# LargeDummyDevice register map
File version: 1.0
Registers are 32-bit, read-write, no defined reset value unless marked. A register's access mark holds for its fields unless they carry their own. Offsets are from the block's base; [hi:lo] are bit positions.

## PERIPHERAL_9
Base 0x40008000
0x04 REG_1 — Register 1
  [32:30] FIELD_11, [32:30] FIELD_14, [31:29] FIELD_5, [28] FIELD_4, [31:28] FIELD_13, [32:28] FIELD_18, [30:27] FIELD_17, [28:26] FIELD_15, [21:20] FIELD_7, [22:20] FIELD_20, [10:9] FIELD_10, [8] FIELD_8, [10:7] FIELD_2, [8:6] FIELD_3, [6:4] FIELD_1, [6:2] FIELD_12, [4:1] FIELD_6, [5:1] FIELD_9, [3:1] FIELD_19, [1:0] FIELD_16
0x08 REG_2 — Register 2
  [2] FIELD_1
0x0C REG_3 — Register 3
  [31] FIELD_7, [31:27] FIELD_19, [24:20] FIELD_28, [18] FIELD_15, [18:17] FIELD_25, [15:14] FIELD_21, [17:13] FIELD_5, [13] FIELD_11, [17:13] FIELD_22, [13:12] FIELD_14, [14:11] FIELD_20, [13:10] FIELD_18, [12:9] FIELD_16, [9] FIELD_26, [11:8] FIELD_1, [9:7] FIELD_4, [7] FIELD_24, [9:6] FIELD_8, [9:6] FIELD_9, [9:6] FIELD_12, [5] FIELD_13, [5] FIELD_23, [5:4] FIELD_27, [5:3] FIELD_10, [2] FIELD_2, [6:2] FIELD_17, [1] FIELD_3, [4:1] FIELD_6
0x10 REG_4 — Register 4
  [34:31] FIELD_16, [33:31] FIELD_22, [35:31] FIELD_27, [31:30] FIELD_2, [33:30] FIELD_5, [34:30] FIELD_12, [33:29] FIELD_11, [30:29] FIELD_15, [31:28] FIELD_24, [28:27] FIELD_8, [29:27] FIELD_25, [27:24] FIELD_29, [17] FIELD_6, [18:17] FIELD_21, [18:16] FIELD_32, [19:15] FIELD_23, [15:14] FIELD_4, [16:14] FIELD_13, [13] FIELD_17, [12] FIELD_20, [15:11] FIELD_18, [13:11] FIELD_26, [8] FIELD_30, [8:7] FIELD_9, [11:7] FIELD_19, [7] FIELD_31, [6:5] FIELD_1, [7:4] FIELD_3, [7:3] FIELD_14, [2:1] FIELD_10, [0] FIELD_7, [0] FIELD_28
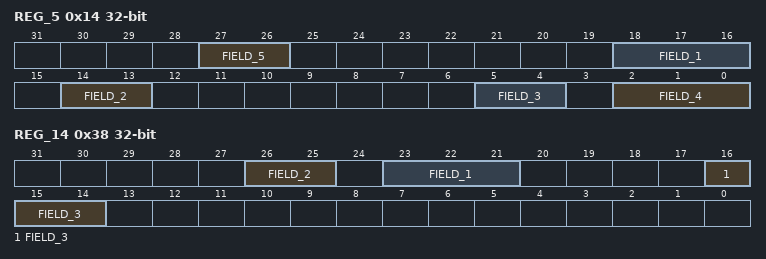
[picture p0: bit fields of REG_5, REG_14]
0x14 REG_5 — Register 5
  [27:26] FIELD_5, [18:16] FIELD_1, [14:13] FIELD_2, [5:4] FIELD_3, [2:0] FIELD_4
0x18 REG_6 — Register 6
  [31:29] FIELD_15, [25:23] FIELD_11, [25:21] FIELD_4, [21] FIELD_5, [25:21] FIELD_18, [24:20] FIELD_13, [20:18] FIELD_10, [18:17] FIELD_7, [16] FIELD_2, [12] FIELD_12, [8:7] FIELD_17, [6] FIELD_3, [6:5] FIELD_16, [4:3] FIELD_9, [5:2] FIELD_14, [5:1] FIELD_1, [1:0] FIELD_6, [1:0] FIELD_8
0x1C REG_7 — Register 7
  [32:31] FIELD_26, [32:29] FIELD_4, [33:29] FIELD_17, [28] FIELD_9, [32:28] FIELD_20, [29:27] FIELD_7, [29:27] FIELD_11, [26] FIELD_12, [29:26] FIELD_21, [27:26] FIELD_29, [29:25] FIELD_1, [26:24] FIELD_2, [25:24] FIELD_13, [20:19] FIELD_15, [19] FIELD_16, [21:19] FIELD_25, [17] FIELD_5, [20:17] FIELD_19, [19:17] FIELD_30, [15] FIELD_23, [14:13] FIELD_6, [12] FIELD_10, [15:12] FIELD_14, [11] FIELD_8, [8:7] FIELD_18, [7:5] FIELD_22, [9:5] FIELD_28, [3:2] FIELD_3, [3:2] FIELD_27, [1] FIELD_24
0x20 REG_8 — Register 8
  [32:31] FIELD_11, [30:26] FIELD_2, [28:26] FIELD_8, [26:24] FIELD_9, [27:23] FIELD_15, [25:22] FIELD_4, [25:21] FIELD_22, [23:21] FIELD_29, [23:20] FIELD_16, [21:20] FIELD_18, [19] FIELD_13, [20:19] FIELD_24, [22:19] FIELD_26, [18] FIELD_1, [20:18] FIELD_19, [15:14] FIELD_12, [13:9] FIELD_21, [8] FIELD_6, [8] FIELD_7, [8:7] FIELD_23, [8:7] FIELD_27, [6] FIELD_14, [5:4] FIELD_17, [7:3] FIELD_5, [7:3] FIELD_10, [4:1] FIELD_3, [2:1] FIELD_25, [1] FIELD_28, [1:0] FIELD_20
0x24 REG_9 — Register 9
  [31:30] FIELD_20, [29:28] FIELD_23, [26:25] FIELD_24, [27:24] FIELD_2, [25:24] FIELD_15, [26:23] FIELD_9, [25:23] FIELD_11, [26:22] FIELD_4, [24:22] FIELD_12, [23:22] FIELD_27, [26:22] FIELD_28, [21] FIELD_6, [23:20] FIELD_17, [22:19] FIELD_13, [22:19] FIELD_21, [18] FIELD_14, [19:17] FIELD_7, [16] FIELD_8, [15] FIELD_16, [10] FIELD_19, [12:9] FIELD_10, [8] FIELD_26, [10:8] FIELD_29, [10:7] FIELD_5, [8:6] FIELD_22, [5:4] FIELD_18, [3] FIELD_1, [7:3] FIELD_3, [3] FIELD_25
0x28 REG_10 — Register 10
  [34:31] FIELD_2, [29:25] FIELD_3, [24:23] FIELD_1, [22:18] FIELD_4, [19:18] FIELD_5, [20:16] FIELD_6, [10:7] FIELD_7
0x2C REG_11 — Register 11
  [33:31] FIELD_30, [30:29] FIELD_6, [31:29] FIELD_20, [26] FIELD_1, [26] FIELD_9, [29:26] FIELD_27, [27:24] FIELD_5, [26:24] FIELD_16, [28:24] FIELD_23, [26:23] FIELD_13, [27:23] FIELD_19, [27:23] FIELD_26, [22] FIELD_25, [24:20] FIELD_18, [23:20] FIELD_28, [23:19] FIELD_4, [19] FIELD_7, [22:18] FIELD_22, [18] FIELD_24, [18] FIELD_29, [21:17] FIELD_8, [17:16] FIELD_2, [17:15] FIELD_15, [16:14] FIELD_12, [14:11] FIELD_11, [12:10] FIELD_17, [9] FIELD_10, [11:7] FIELD_3, [2:1] FIELD_14, [3:0] FIELD_21
0x30 REG_12 — Register 12
  [31] FIELD_1, [30:29] FIELD_2, [23] FIELD_7, [24:20] FIELD_11, [18] FIELD_9, [21:17] FIELD_4, [21:17] FIELD_6, [16:13] FIELD_5, [12:10] FIELD_8, [11:8] FIELD_10, [8:5] FIELD_3, [1] FIELD_12
0x34 REG_13 — Register 13
  [31] FIELD_10, [30:29] FIELD_11, [26:25] FIELD_9, [27:24] FIELD_6, [24:22] FIELD_16, [22:19] FIELD_1, [21:19] FIELD_7, [14] FIELD_3, [18:14] FIELD_15, [16:13] FIELD_13, [12:11] FIELD_5, [11] FIELD_14, [11:10] FIELD_2, [10:6] FIELD_4, [7:5] FIELD_12, [8:4] FIELD_8
0x38 REG_14 — Register 14
  [26:25] FIELD_2, [23:21] FIELD_1, [16:14] FIELD_3
0x3C REG_15 — Register 15
  [33:29] FIELD_4, [30:28] FIELD_2, [31:28] FIELD_21, [27] FIELD_25, [29:26] FIELD_11, [28:24] FIELD_14, [26:23] FIELD_23, [24:20] FIELD_10, [18:17] FIELD_1, [17] FIELD_8, [20:17] FIELD_19, [16:14] FIELD_5, [14] FIELD_6, [15:12] FIELD_9, [15:11] FIELD_3, [12:11] FIELD_16, [10:9] FIELD_13, [12:9] FIELD_22, [10:9] FIELD_24, [9:8] FIELD_17, [11:8] FIELD_18, [10:8] FIELD_20, [5] FIELD_7, [7:3] FIELD_12, [4:1] FIELD_15
0x40 REG_16 — Register 16
  [32:31] FIELD_8, [32:31] FIELD_17, [28] FIELD_6, [26] FIELD_7, [28:26] FIELD_11, [25] FIELD_9, [27:24] FIELD_12, [23:22] FIELD_14, [24:22] FIELD_19, [18] FIELD_20, [21:17] FIELD_23, [16] FIELD_4, [17:13] FIELD_16, [13] FIELD_26, [15:12] FIELD_25, [13:10] FIELD_2, [13:10] FIELD_10, [10:9] FIELD_5, [10:6] FIELD_24, [6:4] FIELD_1, [7:3] FIELD_15, [7:3] FIELD_21, [4:2] FIELD_3, [4:2] FIELD_13, [1] FIELD_18, [2:1] FIELD_22
0x44 REG_17 — Register 17
  [33:31] FIELD_6, [33:31] FIELD_14, [33:31] FIELD_21, [30] FIELD_9, [31:28] FIELD_19, [30:27] FIELD_24, [29:25] FIELD_13, [26:25] FIELD_17, [23:22] FIELD_5, [23:20] FIELD_1, [23:20] FIELD_10, [23:19] FIELD_18, [19:18] FIELD_8, [16:15] FIELD_15, [14] FIELD_11, [11] FIELD_4, [14:10] FIELD_20, [14:10] FIELD_23, [10:9] FIELD_2, [9] FIELD_7, [10:8] FIELD_3, [4] FIELD_16, [7:3] FIELD_12, [0] FIELD_22, [1:0] FIELD_25
0x48 REG_18 — Register 18
  [32:30] FIELD_5, [32:28] FIELD_8, [28:25] FIELD_1, [26:25] FIELD_12, [25:24] FIELD_3, [22:18] FIELD_11, [17:16] FIELD_7, [14] FIELD_14, [17:13] FIELD_2, [12] FIELD_9, [11] FIELD_13, [13:10] FIELD_4, [10:9] FIELD_6, [9:6] FIELD_10
0x4C REG_19 — Register 19
  [31:30] FIELD_7, [25:21] FIELD_6, [22:18] FIELD_10, [20:17] FIELD_2, [19:15] FIELD_4, [13] FIELD_12, [13:10] FIELD_9, [11:9] FIELD_11, [8:6] FIELD_8, [6:5] FIELD_5, [5:4] FIELD_1, [6:4] FIELD_3
0x50 REG_20 — Register 20
  [30:29] FIELD_18, [32:29] FIELD_29, [32:28] FIELD_22, [28:27] FIELD_2, [30:27] FIELD_7, [26] FIELD_3, [30:26] FIELD_10, [25] FIELD_32, [25:24] FIELD_1, [23] FIELD_27, [26:23] FIELD_31, [26:22] FIELD_12, [23:20] FIELD_28, [19] FIELD_8, [21:18] FIELD_20, [19:15] FIELD_13, [17:14] FIELD_25, [16:12] FIELD_6, [11] FIELD_15, [15:11] FIELD_19, [11:10] FIELD_4, [12:10] FIELD_11, [13:10] FIELD_23, [9:8] FIELD_14, [7] FIELD_21, [5] FIELD_16, [5] FIELD_26, [6:4] FIELD_17, [7:4] FIELD_24, [5:4] FIELD_30, [4:2] FIELD_9, [4:1] FIELD_5
0x54 REG_21 — Register 21
  [34:31] FIELD_7, [35:31] FIELD_21, [31:29] FIELD_16, [30:28] FIELD_2, [30:26] FIELD_6, [26] FIELD_20, [27:25] FIELD_3, [26:24] FIELD_12, [26:24] FIELD_15, [24:22] FIELD_14, [23:21] FIELD_24, [20:19] FIELD_26, [18:15] FIELD_9, [14] FIELD_19, [14] FIELD_23, [10] FIELD_18, [10:8] FIELD_1, [8] FIELD_11, [9:5] FIELD_4, [8:5] FIELD_5, [9:5] FIELD_8, [7:3] FIELD_10, [3:2] FIELD_13, [3:2] FIELD_25, [4:1] FIELD_17, [3:1] FIELD_22
0x58 REG_22 — Register 22
  [34:31] FIELD_14, [33:31] FIELD_31, [31:30] FIELD_24, [30:29] FIELD_23, [30:28] FIELD_12, [28] FIELD_15, [29:28] FIELD_17, [29:28] FIELD_20, [29:26] FIELD_2, [27:25] FIELD_13, [25:21] FIELD_21, [20:18] FIELD_16, [18:17] FIELD_4, [17] FIELD_30, [20:16] FIELD_3, [17:16] FIELD_7, [19:15] FIELD_27, [17:14] FIELD_1, [14] FIELD_9, [12] FIELD_25, [14:12] FIELD_28, [12:11] FIELD_5, [11] FIELD_11, [10] FIELD_10, [10] FIELD_29, [5:4] FIELD_22, [7:4] FIELD_26, [7:3] FIELD_8, [6:2] FIELD_6, [4:2] FIELD_19, [2:1] FIELD_18
0x5C REG_23 — Register 23
  [32:29] FIELD_5, [28] FIELD_1, [24:22] FIELD_9, [25:21] FIELD_8, [22:18] FIELD_3, [19:15] FIELD_2, [8] FIELD_6, [8] FIELD_7, [6:4] FIELD_4
0x60 REG_24 — Register 24
  [35:31] FIELD_15, [33:29] FIELD_9, [28] FIELD_13, [29:27] FIELD_2, [31:27] FIELD_5, [30:27] FIELD_18, [28:26] FIELD_25, [29:25] FIELD_12, [23] FIELD_1, [24:23] FIELD_11, [23] FIELD_32, [23:21] FIELD_3, [22:20] FIELD_4, [24:20] FIELD_16, [23:19] FIELD_23, [20:18] FIELD_7, [20:17] FIELD_8, [17:14] FIELD_19, [17:14] FIELD_21, [17:13] FIELD_27, [11] FIELD_22, [15:11] FIELD_29, [10] FIELD_30, [11:8] FIELD_14, [9:7] FIELD_26, [8:6] FIELD_31, [5] FIELD_6, [8:5] FIELD_28, [3] FIELD_10, [4:3] FIELD_24, [2:0] FIELD_17, [2:0] FIELD_20
0x64 REG_25 — Register 25
  [31:29] FIELD_9, [28] FIELD_7, [30:26] FIELD_3, [28:25] FIELD_15, [26:25] FIELD_19, [27:25] FIELD_23, [24:23] FIELD_20, [26:22] FIELD_17, [26:22] FIELD_21, [26:22] FIELD_26, [20:19] FIELD_2, [19] FIELD_11, [19:18] FIELD_24, [15] FIELD_1, [16:14] FIELD_6, [14] FIELD_13, [12] FIELD_10, [13:12] FIELD_22, [12:11] FIELD_5, [15:11] FIELD_18, [10] FIELD_12, [10:9] FIELD_14, [10:6] FIELD_16, [6:2] FIELD_8, [1:0] FIELD_4, [2:0] FIELD_25
0x68 REG_26 — Register 26
  [31:30] FIELD_2, [28:27] FIELD_11, [29:26] FIELD_4, [23:22] FIELD_7, [24:21] FIELD_13, [22:20] FIELD_6, [19:18] FIELD_8, [20:17] FIELD_5, [17:14] FIELD_1, [15:14] FIELD_9, [5] FIELD_10, [6:4] FIELD_12, [3] FIELD_3
0x6C REG_27 — Register 27
  [28] FIELD_11, [27] FIELD_1, [29:27] FIELD_18, [27] FIELD_31, [29:26] FIELD_19, [26] FIELD_25, [27:25] FIELD_6, [28:25] FIELD_23, [27:25] FIELD_30, [25:24] FIELD_20, [25:21] FIELD_32, [23:20] FIELD_14, [21:18] FIELD_7, [19:17] FIELD_27, [18:16] FIELD_2, [19:16] FIELD_17, [18:15] FIELD_4, [14] FIELD_21, [14:13] FIELD_15, [15:12] FIELD_22, [12:11] FIELD_9, [15:11] FIELD_10, [10] FIELD_5, [14:10] FIELD_24, [14:10] FIELD_28, [12:9] FIELD_13, [9] FIELD_26, [10:7] FIELD_8, [11:7] FIELD_16, [4:3] FIELD_29, [5:1] FIELD_3, [4:1] FIELD_12
0x70 REG_28 — Register 28
  [32:31] FIELD_14, [32:30] FIELD_2, [30:28] FIELD_20, [30:27] FIELD_10, [26:25] FIELD_6, [26:25] FIELD_23, [27:25] FIELD_24, [23:22] FIELD_5, [25:22] FIELD_7, [22] FIELD_16, [22:20] FIELD_8, [21:20] FIELD_9, [17] FIELD_17, [17] FIELD_21, [16:14] FIELD_18, [11] FIELD_13, [15:11] FIELD_15, [11:9] FIELD_11, [9] FIELD_12, [7] FIELD_4, [3] FIELD_19, [4:2] FIELD_3, [2] FIELD_22, [0] FIELD_1
0x74 REG_29 — Register 29
  [35:31] FIELD_15, [30:28] FIELD_7, [28:24] FIELD_9, [25:23] FIELD_3, [24:21] FIELD_11, [20] FIELD_13, [22:19] FIELD_8, [21:18] FIELD_2, [18] FIELD_10, [16:12] FIELD_1, [13:10] FIELD_6, [11:8] FIELD_14, [9:6] FIELD_4, [7:6] FIELD_5, [8:6] FIELD_12
